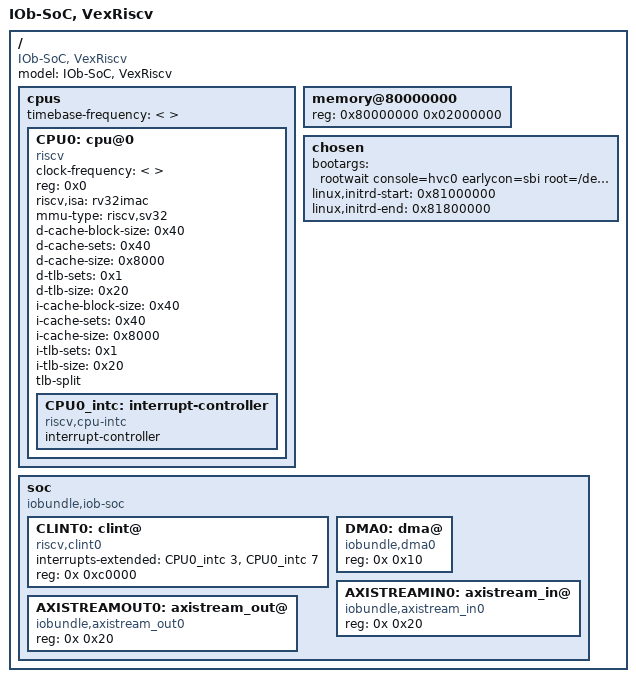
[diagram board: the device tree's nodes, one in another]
// SPDX-License-Identifier: (GPL-2.0 OR MIT)
/* Copyright (c) 2023 Pedro Antunes <pedronmantunes@gmail.com> */
// Device tree for base IOb-SoC-Opencryptolinux system

/dts-v1/;

/ {
    #address-cells = <1>;
    #size-cells = <1>;
    model = "IOb-SoC, VexRiscv";
    compatible = "IOb-SoC, VexRiscv";
    cpus {
        #address-cells = <0x1>;
        #size-cells = <0x0>;
        timebase-frequency = </*FREQ_MACRO*/>;
        CPU0: cpu@0 {
            clock-frequency = </*FREQ_MACRO*/>;
            device_type = "cpu";
            reg = <0x0>;
            status = "okay";
            compatible = "riscv";
            riscv,isa = "rv32imac";
            mmu-type = "riscv,sv32";
            d-cache-block-size = <0x40>;
            d-cache-sets = <0x40>;
            d-cache-size = <0x8000>;
            d-tlb-sets = <0x1>;
            d-tlb-size = <0x20>;
            i-cache-block-size = <0x40>;
            i-cache-sets = <0x40>;
            i-cache-size = <0x8000>;
            i-tlb-sets = <0x1>;
            i-tlb-size = <0x20>;
            tlb-split;
            CPU0_intc: interrupt-controller {
                #address-cells = <0>;
                #interrupt-cells = <1>;
                interrupt-controller;
                compatible = "riscv,cpu-intc";
            };
        };
    };
    memory@80000000 {
        device_type = "memory";
        reg = <0x80000000 0x02000000>; // 26 bits (size of external memory)
    };
    chosen {
        bootargs = "rootwait console=hvc0 earlycon=sbi root=/dev/ram0 init=/sbin/init swiotlb=32 loglevel=8";
        linux,initrd-start = <0x81000000>;
        linux,initrd-end = <0x81800000>; // max 8MB ramdisk image
    };
    soc {
        #address-cells = <1>;
        #size-cells = <1>;
        compatible = "iobundle,iob-soc", "simple-bus";
        ranges;
        // Don't launch driver of UART0 because it's already used by OpenSBI
        //uart0: uart@/*UART0_ADDR_MACRO*/ {
        //    compatible = "ns16550a";
        //    reg = <0x/*UART0_ADDR_MACRO*/ 0x1000>;
        //    clock-frequency = </*FREQ_MACRO*/>;
        //    current-speed = </*BAUD_MACRO*/>;
        ////    interrupt-parent = < &PLIC0 >;
        ////    interrupts = <1>;
        ////    reg-shift = <2>; // regs are spaced on 32 bit boundary
        ////    reg-io-width = <4>; // only 32-bit access are supported
        //};

        // Do we need CLINT0 here? OpenSBI already uses it.
        CLINT0: clint@/*CLINT0_ADDR_MACRO*/ {
            compatible = "riscv,clint0";
            interrupts-extended = < &CPU0_intc 3
                                    &CPU0_intc 7 >;
            reg = <0x/*CLINT0_ADDR_MACRO*/ 0xc0000>;
            reg-names = "control";
        };

        DMA0: dma@/*DMA0_ADDR_MACRO*/ {
            compatible = "iobundle,dma0";
            reg = <0x/*DMA0_ADDR_MACRO*/ 0x10>;
        };

        AXISTREAMIN0: axistream_in@/*AXISTREAMIN0_ADDR_MACRO*/ {
            compatible = "iobundle,axistream_in0";
            reg = <0x/*AXISTREAMIN0_ADDR_MACRO*/ 0x20>;
        };

        AXISTREAMOUT0: axistream_out@/*AXISTREAMOUT0_ADDR_MACRO*/ {
            compatible = "iobundle,axistream_out0";
            reg = <0x/*AXISTREAMOUT0_ADDR_MACRO*/ 0x20>;
        };

        // Do we need PLIC0 here? OpenSBI already uses it.
        //PLIC0: plic@/*PLIC0_ADDR_MACRO*/ {
        //    #address-cells = <0>;
        //    #interrupt-cells = <1>;
        //    compatible = "riscv,plic0";
        //    interrupt-controller;
        //    interrupts-extended = < &CPU0_intc 11
        //                            &CPU0_intc 9 >;
        //    reg = <0x/*PLIC0_ADDR_MACRO*/ 0x4000000>;
        //    reg-names = "control";
        //    riscv,max-priority = <7>;
        //    riscv,ndev = <31>;
        //};
    };
};
